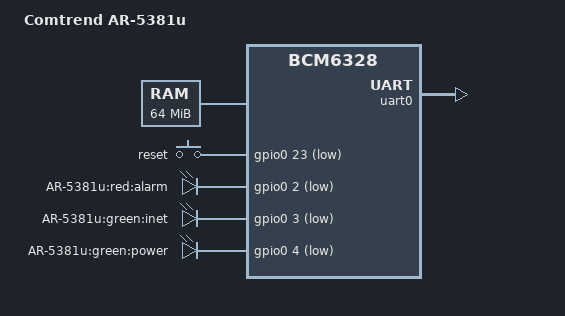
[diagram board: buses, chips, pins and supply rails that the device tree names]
/dts-v1/;

/include/ "bcm6328.dtsi"

/ {
	compatible = "comtrend,ar-5381u", "brcm,bcm6328";
	model = "Comtrend AR-5381u";

	memory@0 {
		device_type = "memory";
		reg = <0x00000000 0x04000000>;
	};

	chosen {
		bootargs = "console=ttyS0,115200";
		stdout-path = &uart0;
	};

	gpio-keys-polled {
		compatible = "gpio-keys-polled";
		#address-cells = <1>;
		#size-cells = <0>;
		poll-interval = <20>;
		debounce-interval = <60>;

		reset {
			label = "reset";
			gpios = <&gpio0 23 1>;
			linux,code = <0x198>;
		};
	};

	gpio-leds {
		compatible = "gpio-leds";

		alarm_red {
			label = "AR-5381u:red:alarm";
			gpios = <&gpio0 2 1>;
		};
		inet_green {
			label = "AR-5381u:green:inet";
			gpios = <&gpio0 3 1>;
		};
		power_green {
			label = "AR-5381u:green:power";
			gpios = <&gpio0 4 1>;
			default-state = "on";
		};
	};
};

&uart0 {
	status = "ok";
};
